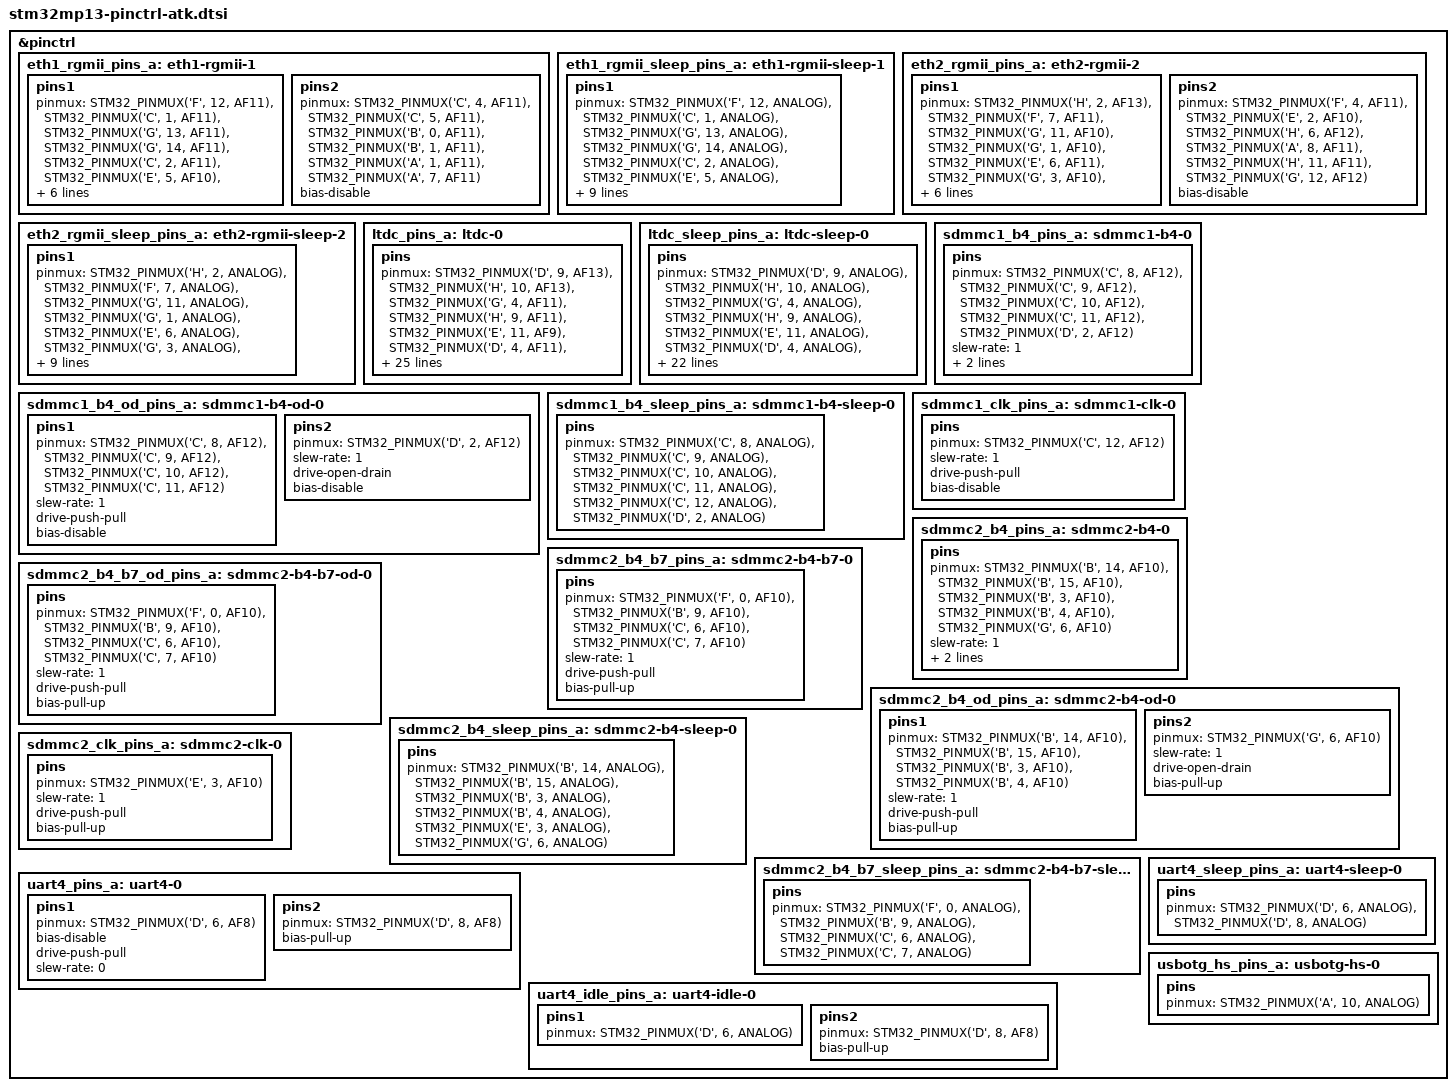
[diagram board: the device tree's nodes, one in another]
// SPDX-License-Identifier: (GPL-2.0+ OR BSD-3-Clause)
/*
 * Copyright (C) STMicroelectronics 2021 - All Rights Reserved
 * Author: Alexandre Torgue <alexandre.torgue@foss.st.com>
 */
#include <dt-bindings/pinctrl/stm32-pinfunc.h>

&pinctrl {
	eth1_rgmii_pins_a: eth1-rgmii-1 {
        pins1 {
            pinmux = <STM32_PINMUX('F', 12, AF11)>, /* ETH1_RGMII_CLK125 */
                 <STM32_PINMUX('C', 1, AF11)>, 	/* ETH1_RGMII_GTX_CLK */
                 <STM32_PINMUX('G', 13, AF11)>, /* ETH1_RGMII_TXD0 */
                 <STM32_PINMUX('G', 14, AF11)>, /* ETH1_RGMII_TXD1 */
                 <STM32_PINMUX('C', 2, AF11)>, 	/* ETH1_RGMII_TXD2 */
                 <STM32_PINMUX('E', 5, AF10)>, 	/* ETH1_RGMII_TXD3 */
                 <STM32_PINMUX('B', 11, AF11)>, /* ETH1_RGMII_TX_CTL */
                 <STM32_PINMUX('A', 2, AF11)>, 	/* ETH1_MDIO */
                 <STM32_PINMUX('G', 2, AF11)>; 	/* ETH1_MDC */
            bias-disable;
            drive-push-pull;
			slew-rate = <2>;
        };
        pins2 {
            pinmux = <STM32_PINMUX('C', 4, AF11)>, /* ETH1_RGMII_RXD0 */
                 <STM32_PINMUX('C', 5, AF11)>, /* ETH1_RGMII_RXD1 */
                 <STM32_PINMUX('B', 0, AF11)>, /* ETH1_RGMII_RXD2 */
                 <STM32_PINMUX('B', 1, AF11)>, /* ETH1_RGMII_RXD3 */
                 <STM32_PINMUX('A', 1, AF11)>, /* ETH1_RGMII_RX_CLK */
                 <STM32_PINMUX('A', 7, AF11)>; /* ETH1_RGMII_RX_CTL */
            bias-disable;
        };
    };

	eth1_rgmii_sleep_pins_a: eth1-rgmii-sleep-1 {
		pins1 {
            pinmux = <STM32_PINMUX('F', 12, ANALOG)>, /* ETH1_RGMII_CLK125 */
                 <STM32_PINMUX('C', 1, ANALOG)>, 	/* ETH1_RGMII_GTX_CLK */
                 <STM32_PINMUX('G', 13, ANALOG)>, 	/* ETH1_RGMII_TXD0 */
                 <STM32_PINMUX('G', 14, ANALOG)>, 	/* ETH1_RGMII_TXD1 */
                 <STM32_PINMUX('C', 2, ANALOG)>, 	/* ETH1_RGMII_TXD2 */
                 <STM32_PINMUX('E', 5, ANALOG)>, 	/* ETH1_RGMII_TXD3 */
                 <STM32_PINMUX('B', 11, ANALOG)>, 	/* ETH1_RGMII_TX_CTL */
                 <STM32_PINMUX('A', 2, ANALOG)>, 	/* ETH1_MDIO */
                 <STM32_PINMUX('G', 2, ANALOG)>, 	/* ETH1_MDC */
				 <STM32_PINMUX('C', 4, ANALOG)>, 	/* ETH1_RGMII_RXD0 */
                 <STM32_PINMUX('C', 5, ANALOG)>, 	/* ETH1_RGMII_RXD1 */
                 <STM32_PINMUX('B', 0, ANALOG)>, 	/* ETH1_RGMII_RXD2 */
                 <STM32_PINMUX('B', 1, ANALOG)>, 	/* ETH1_RGMII_RXD3 */
                 <STM32_PINMUX('A', 1, ANALOG)>, 	/* ETH1_RGMII_RX_CLK */
                 <STM32_PINMUX('A', 7, ANALOG)>; 	/* ETH1_RGMII_RX_CTL */
		};
	};

	eth2_rgmii_pins_a: eth2-rgmii-2 {
		pins1 {
			pinmux = <STM32_PINMUX('H', 2, AF13)>, /* ETH2_RGMII_CLK125 */
				 <STM32_PINMUX('F', 7, AF11)>, 	/* ETH2_RGMII_TXD0 */
				 <STM32_PINMUX('G', 11, AF10)>, /* ETH2_RGMII_TXD1 */
				 <STM32_PINMUX('G', 1, AF10)>, 	/* ETH2_RGMII_TXD2 */
				 <STM32_PINMUX('E', 6, AF11)>, 	/* ETH2_RGMII_TXD3 */
				 <STM32_PINMUX('G', 3, AF10)>, 	/* ETH2_RGMII_GTX_CLK */
				 <STM32_PINMUX('F', 6, AF11)>, 	/* ETH2_RGMII_TX_CTL */
				 <STM32_PINMUX('B', 2, AF11)>, 	/* ETH2_MDIO */
				 <STM32_PINMUX('G', 5, AF10)>; 	/* ETH2_MDC */
			bias-disable;
			drive-push-pull;
			slew-rate = <2>;
		};

		pins2 {
			pinmux = <STM32_PINMUX('F', 4, AF11)>, /* ETH2_RGMII_RXD0 */
				 <STM32_PINMUX('E', 2, AF10)>, 	/* ETH2_RGMII_RXD1 */
				 <STM32_PINMUX('H', 6, AF12)>, 	/* ETH2_RGMII_RXD2 */
				 <STM32_PINMUX('A', 8, AF11)>, 	/* ETH2_RGMII_RXD3 */
				 <STM32_PINMUX('H', 11, AF11)>, /* ETH2_RGMII_RX_CLK */
				 <STM32_PINMUX('G', 12, AF12)>; /* ETH2_RGMII_RX_CTL */
			bias-disable;
		};
	};

	eth2_rgmii_sleep_pins_a: eth2-rgmii-sleep-2 {
		pins1 {
			pinmux = <STM32_PINMUX('H', 2, ANALOG)>, /* ETH2_RGMII_CLK125 */
				 <STM32_PINMUX('F', 7, ANALOG)>, 	/* ETH2_RGMII_TXD0 */
				 <STM32_PINMUX('G', 11, ANALOG)>, 	/* ETH2_RGMII_TXD1 */
				 <STM32_PINMUX('G', 1, ANALOG)>, 	/* ETH2_RGMII_TXD2 */
				 <STM32_PINMUX('E', 6, ANALOG)>, 	/* ETH2_RGMII_TXD3 */
				 <STM32_PINMUX('G', 3, ANALOG)>, 	/* ETH2_RGMII_GTX_CLK */
				 <STM32_PINMUX('F', 6, ANALOG)>, 	/* ETH2_RGMII_TX_CTL */
				 <STM32_PINMUX('B', 2, ANALOG)>, 	/* ETH2_MDIO */
				 <STM32_PINMUX('G', 5, ANALOG)>, 	/* ETH2_MDC */
				 <STM32_PINMUX('F', 4, ANALOG)>, 	/* ETH2_RGMII_RXD0 */
				 <STM32_PINMUX('E', 2, ANALOG)>, 	/* ETH2_RGMII_RXD1 */
				 <STM32_PINMUX('H', 6, ANALOG)>, 	/* ETH2_RGMII_RXD2 */
				 <STM32_PINMUX('A', 8, ANALOG)>, 	/* ETH2_RGMII_RXD3 */
				 <STM32_PINMUX('H', 11, ANALOG)>, 	/* ETH2_RGMII_RX_CLK */
				 <STM32_PINMUX('G', 12, ANALOG)>; 	/* ETH2_RGMII_RX_CTL */
		};
	};

	ltdc_pins_a: ltdc-0 {
		pins {
			pinmux = <STM32_PINMUX('D',  9, AF13)>, /* LCD_CLK */
				 <STM32_PINMUX('H',  10, AF13)>, /* LCD_HSYNC */
				 <STM32_PINMUX('G',  4, AF11)>, /* LCD_VSYNC */ 
				 <STM32_PINMUX('H',  9, AF11)>, /* LCD_DE */
				 <STM32_PINMUX('E', 11, AF9)>,  /* LCD_R0 */
				 <STM32_PINMUX('D',  4, AF11)>, /* LCD_R1 */
				 <STM32_PINMUX('G',  7, AF14)>, /* LCD_R2 */
				 <STM32_PINMUX('B', 12, AF13)>, /* LCD_R3 */
				 <STM32_PINMUX('D', 14, AF14)>, /* LCD_R4 */
				 <STM32_PINMUX('E',  7, AF14)>, /* LCD_R5 */
				 <STM32_PINMUX('E', 13, AF14)>, /* LCD_R6 */
				 <STM32_PINMUX('E',  9, AF14)>, /* LCD_R7 */
				 <STM32_PINMUX('F',  5, AF9)>,  /* LCD_G0 */
				 <STM32_PINMUX('F',  1, AF14)>, /* LCD_G1 */
				 <STM32_PINMUX('H', 13, AF14)>, /* LCD_G2 */
				 <STM32_PINMUX('F',  3, AF14)>, /* LCD_G3 */
				 <STM32_PINMUX('E', 12, AF11)>, /* LCD_G4 */
				 <STM32_PINMUX('G',  0, AF14)>, /* LCD_G5 */
				 <STM32_PINMUX('A', 12, AF14)>, /* LCD_G6 */
				 <STM32_PINMUX('A', 15, AF11)>, /* LCD_G7 */
				 <STM32_PINMUX('D',  5, AF13)>, /* LCD_B0 */
				 <STM32_PINMUX('G',  8, AF7)>,  /* LCD_B1 */
				 <STM32_PINMUX('D', 10, AF14)>, /* LCD_B2 */
				 <STM32_PINMUX('F',  2, AF14)>, /* LCD_B3 */
				 <STM32_PINMUX('G', 15, AF11)>, /* LCD_B4 */
				 <STM32_PINMUX('D', 15, AF14)>, /* LCD_B5 */
				 <STM32_PINMUX('D',  1, AF11)>, /* LCD_B6 */
				 <STM32_PINMUX('E', 15, AF14)>; /* LCD_B7 */
			bias-disable;
			drive-push-pull;
			slew-rate = <1>;
		};
	};

	ltdc_sleep_pins_a: ltdc-sleep-0 {
		pins {
			pinmux = <STM32_PINMUX('D',  9, ANALOG)>, /* LCD_CLK */
				 <STM32_PINMUX('H',  10, ANALOG)>, /* LCD_HSYNC */
				 <STM32_PINMUX('G',  4, ANALOG)>, /* LCD_VSYNC */
				 <STM32_PINMUX('H',  9, ANALOG)>, /* LCD_DE */
				 <STM32_PINMUX('E', 11, ANALOG)>, /* LCD_R0 */
				 <STM32_PINMUX('D',  4, ANALOG)>, /* LCD_R1 */				 
				 <STM32_PINMUX('G',  7, ANALOG)>, /* LCD_R2 */
				 <STM32_PINMUX('B', 12, ANALOG)>, /* LCD_R3 */
				 <STM32_PINMUX('D', 14, ANALOG)>, /* LCD_R4 */
				 <STM32_PINMUX('E',  7, ANALOG)>, /* LCD_R5 */
				 <STM32_PINMUX('E', 13, ANALOG)>, /* LCD_R6 */
				 <STM32_PINMUX('E',  9, ANALOG)>, /* LCD_R7 */
				 <STM32_PINMUX('F',  5, ANALOG)>, /* LCD_G0 */
				 <STM32_PINMUX('F',  1, ANALOG)>, /* LCD_G1 */				 
				 <STM32_PINMUX('H', 13, ANALOG)>, /* LCD_G2 */
				 <STM32_PINMUX('F',  3, ANALOG)>, /* LCD_G3 */
				 <STM32_PINMUX('E', 12, ANALOG)>, /* LCD_G4 */
				 <STM32_PINMUX('G',  0, ANALOG)>, /* LCD_G5 */
				 <STM32_PINMUX('A', 12, ANALOG)>, /* LCD_G6 */
				 <STM32_PINMUX('A', 15, ANALOG)>, /* LCD_G7 */
				 <STM32_PINMUX('D',  5, ANALOG)>, /* LCD_B0 */
				 <STM32_PINMUX('G',  8, ANALOG)>, /* LCD_B1 */				 
				 <STM32_PINMUX('D', 10, ANALOG)>, /* LCD_B2 */
				 <STM32_PINMUX('F',  2, ANALOG)>, /* LCD_B3 */
				 <STM32_PINMUX('G', 15, ANALOG)>, /* LCD_B4 */
				 <STM32_PINMUX('D', 15, ANALOG)>, /* LCD_B5 */
				 <STM32_PINMUX('D',  1, ANALOG)>, /* LCD_B6 */
				 <STM32_PINMUX('E', 15, ANALOG)>; /* LCD_B7 */
		};
	};

	sdmmc1_b4_pins_a: sdmmc1-b4-0 {
		pins {
			pinmux = <STM32_PINMUX('C', 8, AF12)>, /* SDMMC1_D0 */
				 <STM32_PINMUX('C', 9, AF12)>, /* SDMMC1_D1 */
				 <STM32_PINMUX('C', 10, AF12)>, /* SDMMC1_D2 */
				 <STM32_PINMUX('C', 11, AF12)>, /* SDMMC1_D3 */
				 <STM32_PINMUX('D', 2, AF12)>; /* SDMMC1_CMD */
			slew-rate = <1>;
			drive-push-pull;
			bias-disable;
		};
	};

	sdmmc1_b4_od_pins_a: sdmmc1-b4-od-0 {
		pins1 {
			pinmux = <STM32_PINMUX('C', 8, AF12)>, /* SDMMC1_D0 */
				 <STM32_PINMUX('C', 9, AF12)>, /* SDMMC1_D1 */
				 <STM32_PINMUX('C', 10, AF12)>, /* SDMMC1_D2 */
				 <STM32_PINMUX('C', 11, AF12)>; /* SDMMC1_D3 */
			slew-rate = <1>;
			drive-push-pull;
			bias-disable;
		};
		pins2 {
			pinmux = <STM32_PINMUX('D', 2, AF12)>; /* SDMMC1_CMD */
			slew-rate = <1>;
			drive-open-drain;
			bias-disable;
		};
	};

	sdmmc1_b4_sleep_pins_a: sdmmc1-b4-sleep-0 {
		pins {
			pinmux = <STM32_PINMUX('C', 8, ANALOG)>, /* SDMMC1_D0 */
				 <STM32_PINMUX('C', 9, ANALOG)>, /* SDMMC1_D1 */
				 <STM32_PINMUX('C', 10, ANALOG)>, /* SDMMC1_D2 */
				 <STM32_PINMUX('C', 11, ANALOG)>, /* SDMMC1_D3 */
				 <STM32_PINMUX('C', 12, ANALOG)>, /* SDMMC1_CK */
				 <STM32_PINMUX('D', 2, ANALOG)>; /* SDMMC1_CMD */
		};
	};

	sdmmc1_clk_pins_a: sdmmc1-clk-0 {
		pins {
			pinmux = <STM32_PINMUX('C', 12, AF12)>; /* SDMMC1_CK */
			slew-rate = <1>;
			drive-push-pull;
			bias-disable;
		};
	};

	sdmmc2_b4_pins_a: sdmmc2-b4-0 {
		pins {
			pinmux = <STM32_PINMUX('B', 14, AF10)>, /* SDMMC2_D0 */
				 <STM32_PINMUX('B', 15, AF10)>, /* SDMMC2_D1 */
				 <STM32_PINMUX('B', 3, AF10)>, /* SDMMC2_D2 */
				 <STM32_PINMUX('B', 4, AF10)>, /* SDMMC2_D3 */
				 <STM32_PINMUX('G', 6, AF10)>; /* SDMMC2_CMD */
			slew-rate = <1>;
			drive-push-pull;
			bias-pull-up;
		};
	};

	sdmmc2_b4_b7_pins_a: sdmmc2-b4-b7-0 {
		pins {
			pinmux = <STM32_PINMUX('F', 0, AF10)>, /* SDMMC2_D4 */
				 <STM32_PINMUX('B', 9, AF10)>, /* SDMMC2_D5 */
				 <STM32_PINMUX('C', 6, AF10)>, /* SDMMC2_D6 */				 
				 <STM32_PINMUX('C', 7, AF10)>; /* SDMMC2_D7 */
			slew-rate = <1>;
			drive-push-pull;
			bias-pull-up;
		};
	};

	sdmmc2_b4_od_pins_a: sdmmc2-b4-od-0 {
		pins1 {
			pinmux = <STM32_PINMUX('B', 14, AF10)>, /* SDMMC2_D0 */
				 <STM32_PINMUX('B', 15, AF10)>, /* SDMMC2_D1 */
				 <STM32_PINMUX('B', 3, AF10)>, /* SDMMC2_D2 */
				 <STM32_PINMUX('B', 4, AF10)>; /* SDMMC2_D3 */
			slew-rate = <1>;
			drive-push-pull;
			bias-pull-up;
		};
		pins2 {
			pinmux = <STM32_PINMUX('G', 6, AF10)>; /* SDMMC2_CMD */
			slew-rate = <1>;
			drive-open-drain;
			bias-pull-up;
		};
	};

	sdmmc2_b4_b7_od_pins_a: sdmmc2-b4-b7-od-0 {
		pins {
			pinmux = <STM32_PINMUX('F', 0, AF10)>, /* SDMMC2_D4 */
				 <STM32_PINMUX('B', 9, AF10)>, /* SDMMC2_D5 */
				 <STM32_PINMUX('C', 6, AF10)>, /* SDMMC2_D6 */				 
				 <STM32_PINMUX('C', 7, AF10)>; /* SDMMC2_D7 */
			slew-rate = <1>;
			drive-push-pull;
			bias-pull-up;
		};
	};	

	sdmmc2_b4_sleep_pins_a: sdmmc2-b4-sleep-0 {
		pins {
			pinmux = <STM32_PINMUX('B', 14, ANALOG)>, /* SDMMC2_D0 */
				 <STM32_PINMUX('B', 15, ANALOG)>, /* SDMMC2_D1 */
				 <STM32_PINMUX('B', 3, ANALOG)>, /* SDMMC2_D2 */
				 <STM32_PINMUX('B', 4, ANALOG)>, /* SDMMC2_D3 */
				 <STM32_PINMUX('E', 3, ANALOG)>, /* SDMMC2_CK */
				 <STM32_PINMUX('G', 6, ANALOG)>; /* SDMMC2_CMD */
		};
	};

	sdmmc2_b4_b7_sleep_pins_a: sdmmc2-b4-b7-sleep-0 {
		pins {
			pinmux = <STM32_PINMUX('F', 0, ANALOG)>, /* SDMMC2_D4 */
				 <STM32_PINMUX('B', 9, ANALOG)>, /* SDMMC2_D5 */
				 <STM32_PINMUX('C', 6, ANALOG)>, /* SDMMC2_D6 */				 
				 <STM32_PINMUX('C', 7, ANALOG)>; /* SDMMC2_D7 */
		};
	};

	sdmmc2_clk_pins_a: sdmmc2-clk-0 {
		pins {
			pinmux = <STM32_PINMUX('E', 3, AF10)>; /* SDMMC2_CK */
			slew-rate = <1>;
			drive-push-pull;
			bias-pull-up;
		};
	};

	uart4_pins_a: uart4-0 {
		pins1 {
			pinmux = <STM32_PINMUX('D', 6, AF8)>; /* UART4_TX */
			bias-disable;
			drive-push-pull;
			slew-rate = <0>;
		};
		pins2 {
			pinmux = <STM32_PINMUX('D', 8, AF8)>; /* UART4_RX */
			bias-pull-up;
		};
	};

	uart4_idle_pins_a: uart4-idle-0 {
		pins1 {
			pinmux = <STM32_PINMUX('D', 6, ANALOG)>; /* UART4_TX */
		};
		pins2 {
			pinmux = <STM32_PINMUX('D', 8, AF8)>; /* UART4_RX */
			bias-pull-up;
		};
	};

	uart4_sleep_pins_a: uart4-sleep-0 {
		pins {
			pinmux = <STM32_PINMUX('D', 6, ANALOG)>, /* UART4_TX */
				 <STM32_PINMUX('D', 8, ANALOG)>; /* UART4_RX */
		};
	};

	usbotg_hs_pins_a: usbotg-hs-0 {
		pins {
			pinmux = <STM32_PINMUX('A', 10, ANALOG)>; /* OTG_ID */
		};
	};
};
